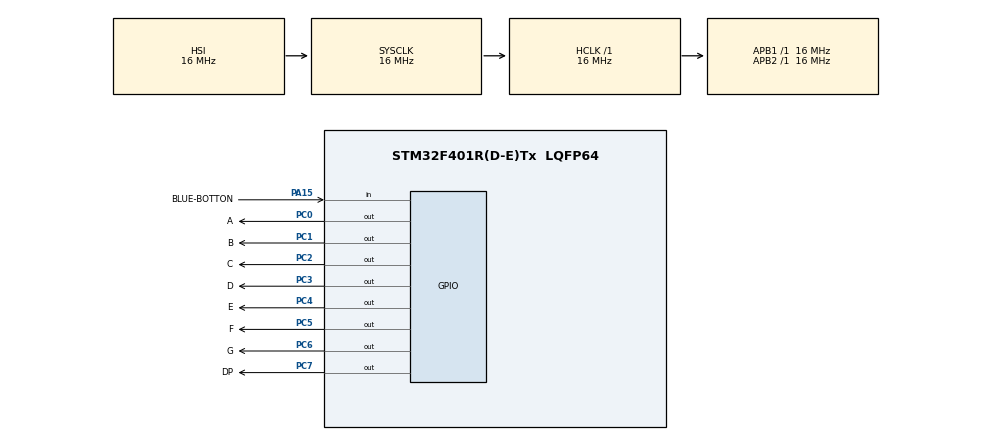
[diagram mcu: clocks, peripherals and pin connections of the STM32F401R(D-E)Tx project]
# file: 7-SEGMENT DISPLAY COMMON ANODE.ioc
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Mcu.Family=STM32F4
PC7.GPIO_ModeDefaultOutputPP=GPIO_MODE_OUTPUT_OD
RCC.CortexFreq_Value=16000000
PC4.PinState=GPIO_PIN_SET
PC4.Signal=GPIO_Output
PC2.Signal=GPIO_Output
PC6.Signal=GPIO_Output
PC0.GPIO_Label=A
PC6.GPIO_Label=G
PC0.GPIO_ModeDefaultOutputPP=GPIO_MODE_OUTPUT_OD
PC2.GPIO_Speed=GPIO_SPEED_FREQ_LOW
PC0.Signal=GPIO_Output
PC3.GPIO_Speed=GPIO_SPEED_FREQ_LOW
ProjectManager.StackSize=0x400
PC3.PinState=GPIO_PIN_SET
PA13.Signal=SYS_JTMS-SWDIO
PA15.GPIO_Label=BLUE-BOTTON
PC0.GPIO_Speed=GPIO_SPEED_FREQ_LOW
ProjectManager.TargetToolchain=STM32CubeIDE
PC7.Signal=GPIO_Output
PC3.Signal=GPIO_Output
PC1.PinState=GPIO_PIN_SET
RCC.LSE_VALUE=32768
RCC.AHBFreq_Value=16000000
PC6.PinState=GPIO_PIN_SET
RCC.HSE_VALUE=25000000
board=custom
PC7.GPIO_Speed=GPIO_SPEED_FREQ_LOW
RCC.VCOOutputFreq_Value=192000000
PC4.GPIO_Speed=GPIO_SPEED_FREQ_LOW
RCC.APB2Freq_Value=16000000
PC4.GPIO_Label=E
PA14.Mode=Serial_Wire
PC1.GPIO_Label=B
PC7.PinState=GPIO_PIN_SET
PC1.GPIO_Speed=GPIO_SPEED_FREQ_LOW
PA13.Mode=Serial_Wire
Mcu.Name=STM32F401R(D-E)Tx
PC7.GPIO_Label=DP
RCC.SYSCLKFreq_VALUE=16000000
Mcu.Package=LQFP64
PC2.PinState=GPIO_PIN_SET
PC5.PinState=GPIO_PIN_SET
PC5.GPIO_Label=F
PA14.Signal=SYS_JTCK-SWCLK
PA15.Signal=GPIO_Input
ProjectManager.HeapSize=0x200
RCC.HSI_VALUE=16000000
PC1.GPIO_ModeDefaultOutputPP=GPIO_MODE_OUTPUT_OD
NVIC.PriorityGroup=NVIC_PRIORITYGROUP_4
PC5.GPIO_Speed=GPIO_SPEED_FREQ_LOW
PA15.GPIO_PuPd=GPIO_PULLUP
PC2.GPIO_ModeDefaultOutputPP=GPIO_MODE_OUTPUT_OD
PC3.GPIO_Label=D
PC5.Signal=GPIO_Output
PC3.GPIO_ModeDefaultOutputPP=GPIO_MODE_OUTPUT_OD
PC4.GPIO_ModeDefaultOutputPP=GPIO_MODE_OUTPUT_OD
RCC.APB1Freq_Value=16000000
PC5.GPIO_ModeDefaultOutputPP=GPIO_MODE_OUTPUT_OD
PC6.GPIO_Speed=GPIO_SPEED_FREQ_LOW
PC2.GPIO_Label=C
PC0.PinState=GPIO_PIN_SET
PC1.Signal=GPIO_Output
PC6.GPIO_ModeDefaultOutputPP=GPIO_MODE_OUTPUT_OD

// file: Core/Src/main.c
/* USER CODE BEGIN Header */
/**
 * CODE TO DISPLAY THE NUMBERS BETWEEN 0 AND 9 WITH A 7-SEGMENT DISPLAY ANODE COMMON
 * WITH A PUSH-BUTTON TO CHANGE THE NUMBER
  ******************************************************************************
  * @file           : main.c
  * @brief          : Main program body
  ******************************************************************************
  * @attention
  *
  * <h2><center>&copy; Copyright (c) 2021 STMicroelectronics.
  * All rights reserved.</center></h2>
  *
  * This software component is licensed by ST under BSD 3-Clause license,
  * the "License"; You may not use this file except in compliance with the
  * License. You may obtain a copy of the License at:
  *                        opensource.org/licenses/BSD-3-Clause
  *
  ******************************************************************************
  */
/* USER CODE END Header */
#include "main.h"
#include "gpio.h"

void SystemClock_Config(void);

int main(void)
{
  /* USER CODE BEGIN 1 */

	//The numbers variable stores the binary code  needed to show a number on the display
	//The Bitwise complement operator(~) is used to change the 1s to 0 because
	// we are using outputs with open-drain mode, so we need some outputs to be 0 to make the pattern
	// of a number. For example  0 =0011 1111 and after the ~ 0 = 1100 0000.
	unsigned char numbers[10]={~0x3F,~0x06,~0x5B,~0x4F,~0x66,~0x6D,~0x7D,~0x07,~0x7F,~0x6F};
	//The value of the number control variable says which number will be displayed and
	//this value is changed by the button.
	unsigned char number_control=0;

  /* USER CODE END 1 */

  /* MCU Configuration--------------------------------------------------------*/

  /* Reset of all peripherals, Initializes the Flash interface and the Systick. */
  HAL_Init();

  /* Configure the system clock */
  SystemClock_Config();

  /* Initialize all configured peripherals */
  MX_GPIO_Init();

  /* Infinite loop */
  while (1)
  {

    /* USER CODE BEGIN 3 */
	  //Changing with a button  the number that has to be displayed
	  //BEGIN CHANGING NUMBER
	  if(HAL_GPIO_ReadPin(BLUE_BOTTON_GPIO_Port, BLUE_BOTTON_Pin)== GPIO_PIN_RESET  )
	  {
		  if(number_control < 9)
		  {
		  number_control++;
		  }
		  //With this else we go back to 0 when we are already displaying the number 9 and we press the button.
		  else
		  {
			  number_control=0;
		  }
		  //With this infinite loop we eliminate the bounce effect made by the button
		  //This happens because when we press the button the capacitor is discharged and the pin state is 0,
		  //so at this time the program get in the if statement and change the value of number control variable,
		  //then when we stop pressing the button the code is in the infinite loop, we wait until the pin is
		  //in the hight state, like that we force the pin input to be 0 and 1.
		  while (1)
		 {
			  if(HAL_GPIO_ReadPin(BLUE_BOTTON_GPIO_Port, BLUE_BOTTON_Pin)== GPIO_PIN_SET  )
			  {
				  break;
			  }
		  }
	  }
	  //END CHANGING NUMBER

	  //BEGIN SHOWING NUMBER
	  /*With this function, we set the pins to show a number. I add a type casting to convert the char variable
	   *to uint32_t variable and like that the function can accept the variable */
	  LL_GPIO_WriteOutputPort(GPIOC, ((uint32_t)numbers[number_control]));

	  //END SHOWING NUMBER

  }
  /* USER CODE END 3 */
}

void SystemClock_Config(void)
{
  RCC_OscInitTypeDef RCC_OscInitStruct = {0};
  RCC_ClkInitTypeDef RCC_ClkInitStruct = {0};

  /** Configure the main internal regulator output voltage
  */
  __HAL_RCC_PWR_CLK_ENABLE();
  __HAL_PWR_VOLTAGESCALING_CONFIG(PWR_REGULATOR_VOLTAGE_SCALE2);
  /** Initializes the RCC Oscillators according to the specified parameters
  * in the RCC_OscInitTypeDef structure.
  */
  RCC_OscInitStruct.OscillatorType = RCC_OSCILLATORTYPE_HSI;
  RCC_OscInitStruct.HSIState = RCC_HSI_ON;
  RCC_OscInitStruct.HSICalibrationValue = RCC_HSICALIBRATION_DEFAULT;
  RCC_OscInitStruct.PLL.PLLState = RCC_PLL_NONE;
  if (HAL_RCC_OscConfig(&RCC_OscInitStruct) != HAL_OK)
  {
    Error_Handler();
  }
  /** Initializes the CPU, AHB and APB buses clocks
  */
  RCC_ClkInitStruct.ClockType = RCC_CLOCKTYPE_HCLK|RCC_CLOCKTYPE_SYSCLK
                              |RCC_CLOCKTYPE_PCLK1|RCC_CLOCKTYPE_PCLK2;
  RCC_ClkInitStruct.SYSCLKSource = RCC_SYSCLKSOURCE_HSI;
  RCC_ClkInitStruct.AHBCLKDivider = RCC_SYSCLK_DIV1;
  RCC_ClkInitStruct.APB1CLKDivider = RCC_HCLK_DIV1;
  RCC_ClkInitStruct.APB2CLKDivider = RCC_HCLK_DIV1;

  if (HAL_RCC_ClockConfig(&RCC_ClkInitStruct, FLASH_LATENCY_0) != HAL_OK)
  {
    Error_Handler();
  }
}

void Error_Handler(void)
{
  __disable_irq();
  while (1)
  {
  }
}

/************************ (C) COPYRIGHT STMicroelectronics *****END OF FILE****/
